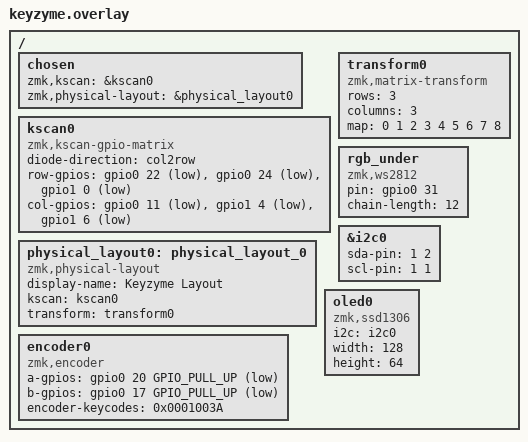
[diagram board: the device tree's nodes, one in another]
#include <dt-bindings/gpio/gpio.h>

/ {
    chosen {
        zmk,kscan = &kscan0;
        zmk,physical-layout = &physical_layout0;
    };

    kscan0: kscan0 {
        compatible = "zmk,kscan-gpio-matrix";
        diode-direction = "col2row";

        row-gpios = <&gpio0 22 GPIO_ACTIVE_LOW>,
                    <&gpio0 24 GPIO_ACTIVE_LOW>,
                    <&gpio1 0  GPIO_ACTIVE_LOW>;

        col-gpios = <&gpio0 11 GPIO_ACTIVE_LOW>,
                    <&gpio1 4  GPIO_ACTIVE_LOW>,
                    <&gpio1 6  GPIO_ACTIVE_LOW>;
    };

    transform0: transform0 {
        compatible = "zmk,matrix-transform";
        rows = <3>;
        columns = <3>;
        map = <
            0 1 2
            3 4 5
            6 7 8
        >;
    };

    physical_layout0: physical_layout_0 {
        compatible = "zmk,physical-layout";
        display-name = "Keyzyme Layout";
        kscan = <&kscan0>;
        transform = <&transform0>;
    };

    encoder0: encoder0 {
        compatible = "zmk,encoder";
        a-gpios = <&gpio0 20 GPIO_PULL_UP GPIO_ACTIVE_LOW>;
        b-gpios = <&gpio0 17 GPIO_PULL_UP GPIO_ACTIVE_LOW>;
        encoder-keycodes = <0x0001003A>; // F1
    };

    rgb_under: rgb_under {
        compatible = "zmk,ws2812";
        pin = <&gpio0 31>;
        chain-length = <12>;
    };

    &i2c0 {
        status = "okay";
        sda-pin = <1 2>;
        scl-pin = <1 1>;
    };

    oled0: oled0 {
        compatible = "zmk,ssd1306";
        i2c = <&i2c0>;
        width = <128>;
        height = <64>;
    };
};
